# afe register map
Registers are 8-bit, access not given, no defined reset value unless marked. A register's access mark holds for its fields unless they carry their own. Offsets are from the block's base; lines under a group give offsets from that group; [hi:lo] are bit positions; {n}, {i} and the like mark numbered series; 'fields as' and 'values as' point back to an identical list; <NAME> marks a mode.

## Memory map
0x00000000 afe — PAN2G5 AFE registers

## afe — PAN2G5 AFE registers
Base 0x00000000
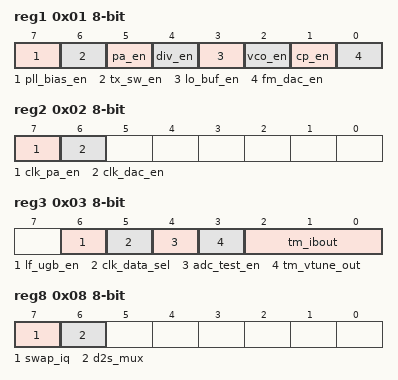
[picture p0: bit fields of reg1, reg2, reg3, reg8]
0x01 reg1
  [7] pll_bias_en — PLL Bias Enable
  [6] tx_sw_en — TX RF Switch Enable
  [5] pa_en — PA enable
  [4] div_en — Divider enable
  [3] lo_buf_en — LO buffer enable
  [2] vco_en — VCO enable
  [1] cp_en — Charge pump enable
  [0] fm_dac_en — FM DAC Enable
0x02 reg2
  [7] clk_pa_en — PA clock gating
  [6] clk_dac_en — DAC clock gating
0x03 reg3
  [6] lf_ugb_en — VCO VTUNE control.Forces VTUNE to VDD/2.
  [5] clk_data_sel — CLK_DATA_OUT Source.
    0=clk_data; 1=xo_out
  [4] adc_test_en — ADC Test Enable.
  [3] tm_vtune_out
  [2:0] tm_ibout — selects the analog signal connected to TM_PLL_IB. To measure current the associated EN signal must be low.
    0=gnd_vco; 1=ib_vco; 2=ib_cp; 3=ib_fm_mod; 4=ib_lobuf; 5=ib_div; 6=ib_ref; 7=ib_mon
0x04 reg4
  [4:3] cp_ofs — Charge-pump offset current option (Inverse)
0x05 reg5
  [7:6] tm_fmdac_out — Enables FM DAC measurements. Diff on SWADC or single ended on ana_out_vtune.
0x06 reg6
0x07 reg7
  [5] pvtd_en
  [4:0] pvtd_trm
  [4:0] sw_adc_mux — Mux select for SW_ADC_OUTPUT on RXOUT_D8:0
    0=sw_adc; 1=adc_flag_i; 2=adc_flag_q; 3=tx_fb_out_d; 4=pvtd_flag; 5=pvtd_out_d
0x08 reg8
  [7] swap_iq — swap the IQ offset registers, REGA9 and REGA10.
  [6] d2s_mux — RX Output Buffer Select.
    0=if_mixer; 1=lpf
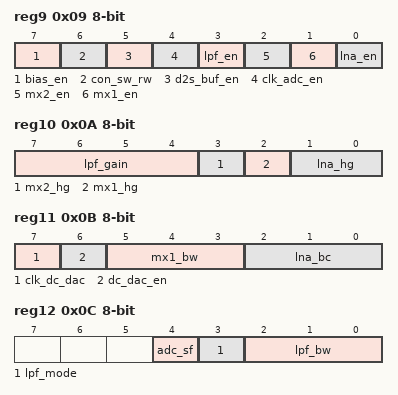
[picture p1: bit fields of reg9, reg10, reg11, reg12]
0x09 reg9
  [7] bias_en
  [6] con_sw_rw — RX_RF Switch EN.
  [5] d2s_buf_en
  [4] clk_adc_en
  [3] lpf_en
  [2] mx2_en — mx2_en IF Mixer
  [1] mx1_en — mx1_en RF Mixer
  [0] lna_en
0x0A reg10
  [7:4] lpf_gain
    0=0dB; 1=3dB; 2=6dB; 3=9dB; 4=12dB; 5=15dB; 6=18dB; 7=21dB; 8=24dB; 9=27dB; 10=30dB; 11=33dB; 12=36dB
  [3] mx2_hg — IF Mixer: 12dB.
  [2] mx1_hg — RF mixer : 12dB
  [1:0] lna_hg
    0=n15_3; 1=1_5; 2=12_7; 3=24
0x0B reg11
  [7] clk_dc_dac
  [6] dc_dac_en
  [5:3] mx1_bw — RF Mixer Output Bandwidth.
  [2:0] lna_bc — LNA Tank.
0x0C reg12
  [4] adc_sf — ADC Sampling Frequency.
    0=4_8M (4.8 MHz.); 1=8M (8 MHz.)
  [3] lpf_mode — LPF Nominal BW Mode
    0=500 KHz; 1=1m (1 MHz.)
  [2:0] lpf_bw — LPF filter BW Fine Control.
    0=0_76_BW; 4=1_0_BW; 7=1_66_BW
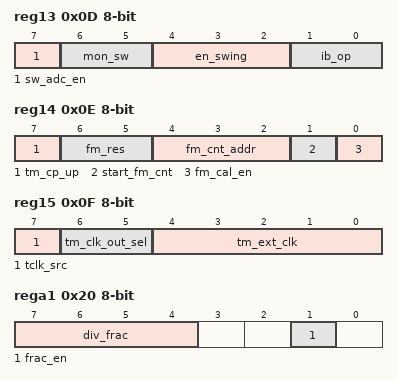
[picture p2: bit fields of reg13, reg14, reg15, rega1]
0x0D reg13
  [7] sw_adc_en
  [6:5] mon_sw
    0=IQ; 1=sw_adc; 3=fm_cnt
  [4:2] en_swing
    0=Hiz; 1=pll_tx_vco; 2=pll_lobuf; 3=pll_fm_dac; 5=lpf_cm; 6=vtune; 7=vss
  [1:0] ib_op
0x0E reg14
  [7] tm_cp_up, [6:5] fm_res, [4:2] fm_cnt_addr, [1] start_fm_cnt, [0] fm_cal_en
0x0F reg15
  [7] tclk_src, [6:5] tm_clk_out_sel, [4:0] tm_ext_clk
0x20 rega1
  [7:4] div_frac — Fractional part of dividing ratio for center frequency (bit [3 .. 0]). DivRatio = Freq/2/Fref 2.44G/2/24.0M = 50.8333
  [1] frac_en
0x21 rega2
  [7:0] div_frac — Fractional part of dividing ratio for center frequency (bit [11 .. 4]).
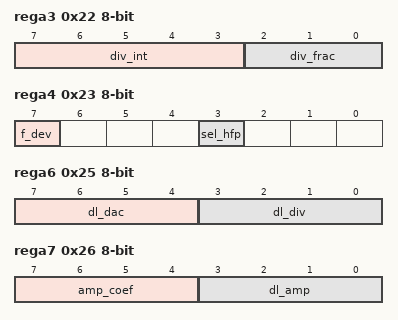
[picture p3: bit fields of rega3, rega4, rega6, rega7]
0x22 rega3
  [7:3] div_int — Integer part of dividing ratio for center frequency. Int(DivRation)-32 50-32=18.
  [2:0] div_frac — Fractional part of dividing ratio for center frequency (bit [14.. 12]). Frac(DivRation)*2^15 0.8333*2^15=27306.7 Round to 27307.
0x23 rega4
  [7] f_dev — Frequency deviation calculated by FDEV = Fclk * 2 / 2^15 * (F_DEV+1) for both FSK and PSK mode (bit [0])
  [3] sel_hfp — 1: external frequency modulation path input; 0: data is provided by PBRS gen
    1=fm_en (Enable FM Data path.); 0=fm_dis (FM Data path is disabled.)
0x24 rega5
  [7:0] f_dev — Frequency deviation calculated by FDEV = Fclk * 2 / 2^15 * (F_DEV+1) for both FSK and PSK mode (bit [8.. 1]). p_dev_coef: scaling factor for the fm data path 0 to 1.996.
0x25 rega6
  [7:4] dl_dac — Timing delay setting for high-frequency phase modulation path 0000: no delay 0001 - 1111: 1 ~ 15 * 1 / Fclk delay. HF Phase Mod Delay.
  [3:0] dl_div — Timing delay setting for low-frequency phase modulation path 0000: no delay 0001 - 1111: 1 ~ 15 * 1 / Fclk delay. LF Phase Mod Delay.
0x26 rega7
  [7:4] amp_coef — Scaling factor in Amp path
  [3:0] dl_amp — Timing delay setting for amplitude modulation path 0000: no delay 0001 - 1111: 1 ~ 15 * 1 / Fclk delay
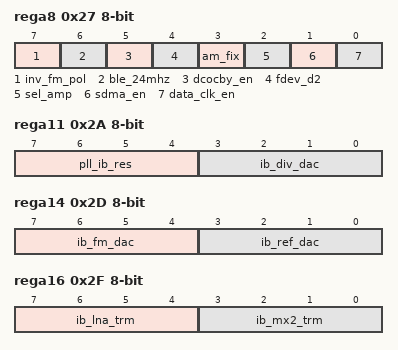
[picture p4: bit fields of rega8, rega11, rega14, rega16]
0x27 rega8
  [7] inv_fm_pol — inverts the polarity of the HF FM DATA Path.
    1=inv (Infverted from LF Path.); 0=non_inv (Same polarity from LF Path.)
  [6] ble_24mhz — Select crystal frequency.
    1=24m (Selects 24MHz crystal.); 0=32m (Selects 32MHz crystal.)
  [5] dcocby_en — Enable Bypassing Digital DC Offset Compensation for AGC path
    1=en (Enable.); 0=dis (Disable.)
  [4] fdev_d2 — No AFE Function DBBTop2: 2x FM_DATA
    0=2k (2kHz resolution for high frequency path.); 1=4k (4kHz resolution for high frequency path.)
  [3] am_fix
    1=amp_coef (output fixed value to amplitude modulation path defined by AMP_COEF.); 0=internal (data is provided internally.)
  [2] sel_amp — 1: external data input 0: data is provided internally
    0=internal (Internatl data pwd.); 1=external data
  [1] sdma_en — 1: enable Sigma Delta Modulator for amplitude modulation path 0: disable (through)
  [0] data_clk_en — 1: enable Data clock generator ; 0: disable
0x28 rega9 — rega9 *signed*
  [7:0] dc_i — 2s complement RX-I Offset Trim.
0x29 rega10 — rega10 *signed*
  [7:0] dc_q — 2s complement RX-Q Offset Trim.
0x2A rega11
  [7:4] pll_ib_res — Adjusts the resistor in the soruce lead of the pll bias generator.
  [3:0] ib_div_dac — Adjusts the resistor connected to the gate in the pll bias generator.
0x2B rega12
  [6:0] ib_vdo_dac — 16u - 47.5u. 0.5u step
0x2C rega13
  [4:0] ib_cp_dac — 4u - 19.5u. 0.5u step
0x2D rega14
  [7:4] ib_fm_dac — 5u - 42.5u. 0.5u step
  [3:0] ib_ref_dac — 0.625u - 10u. 0.5u step
0x2E rega15
  [6:0] ib_lobuf_dac — 4u - 35.5u. 0.5u step
0x2F rega16
  [7:4] ib_lna_trm, [3:0] ib_mx2_trm
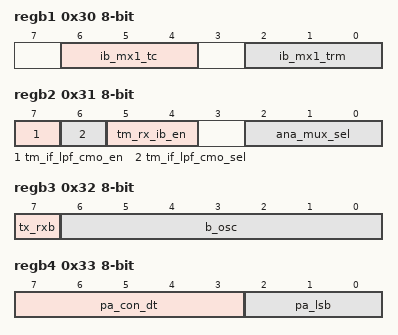
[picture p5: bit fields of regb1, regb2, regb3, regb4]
0x30 regb1
  [6:4] ib_mx1_tc, [2:0] ib_mx1_trm
0x31 regb2
  [7] tm_if_lpf_cmo_en — Enables IF LPF common mode Out on ADC or ana_out_vtune.
  [6] tm_if_lpf_cmo_sel — selects source of ADC or ana_out_vtune.
    0=q; 1=i
  [5:4] tm_rx_ib_en — Selects the RX current attached to TM_RX_IB.
    0=gnd_mx2; 1=lna_ib; 2=rf_mixer_ib; 3=if_mixer_ib
  [2:0] ana_mux_sel — selects the signal connected to ana_rffe_out.
    0=gnd_ana; 1=tm_rx_ib; 2=tm_pll_ib; 3=if_cm; 4=lpf_cm; 5=vtune_out
0x32 regb3
  [7] tx_rxb — Scales current in VCO.
  [6:0] b_osc — PLL VCO Bank Selection.
0x33 regb4
  [7:3] pa_con_dt, [2:0] pa_lsb
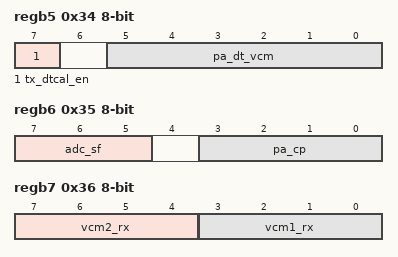
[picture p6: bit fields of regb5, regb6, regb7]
0x34 regb5
  [7] tx_dtcal_en, [5:0] pa_dt_vcm
0x35 regb6
  [7:5] adc_sf — ADC clock rate selection.
    0=d2; 1=d3; 2=d4; 3=d6; 4=d8
  [3:0] pa_cp
0x36 regb7
  [7:4] vcm2_rx — Common Mode for BB.
  [3:0] vcm1_rx — Common Mode Control for IF Mixer, LPF, and output buffer. 350mV - 650mV 45 mV step.
